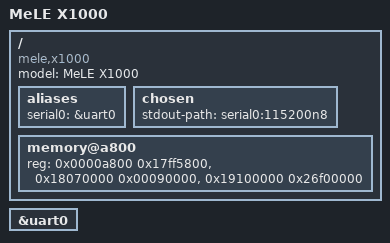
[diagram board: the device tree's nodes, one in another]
// SPDX-License-Identifier: (GPL-2.0-or-later OR BSD-2-Clause)
/*
 * Copyright (c) 2017-2019 Andreas Färber
 */

/dts-v1/;

#include "rtd1195.dtsi"

/ {
	compatible = "mele,x1000", "realtek,rtd1195";
	model = "MeLE X1000";

	aliases {
		serial0 = &uart0;
	};

	chosen {
		stdout-path = "serial0:115200n8";
	};

	memory@a800 {
		device_type = "memory";
		reg = <0x0000a800 0x17ff5800>, /* boot ROM to r-bus */
		      <0x18070000 0x00090000>, /* r-bus to NOR flash */
		      <0x19100000 0x26f00000>; /* NOR flash to 1 GiB */
	};
};

&uart0 {
	status = "okay";
};
